# PIC32CX2051BZ66048 register map
Vendor: Microchip Technology; Series: PIC32CXBZ66; File version: 0
CPU: CM4 r0p1, little endian, MPU, FPU, 3 interrupt priority bits, 58 interrupts
Registers are 32-bit, read-write, reset 0x0 unless marked. A register's access mark holds for its fields unless they carry their own. Offsets are from the block's base; [hi:lo] are bit positions; {n}, {i} and the like mark numbered series.

## GPIOE — GPIO
Base 0x44002D00; register names take the prefix GPIO_
Same registers: GPIOA 0x44002900, GPIOB 0x44002A00, GPIOC 0x44002B00, GPIOD 0x44002C00
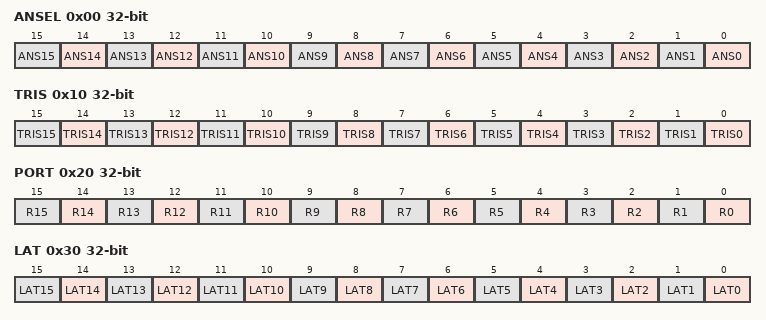
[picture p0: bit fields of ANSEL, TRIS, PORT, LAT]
0x00 ANSEL
  [n] ANS{n} (n=0..15)
0x04 ANSELCLR
0x08 ANSELSET
0x0C ANSELINV
0x10 TRIS
  [n] TRIS{n} (n=0..15)
0x14 TRISCLR
0x18 TRISSET
0x1C TRISINV
0x20 PORT
  [n] R{n} (n=0..15)
0x24 PORTCLR
0x28 PORTSET
0x2C PORTINV
0x30 LAT
  [n] LAT{n} (n=0..15)
0x34 LATCLR
0x38 LATSET
0x3C LATINV
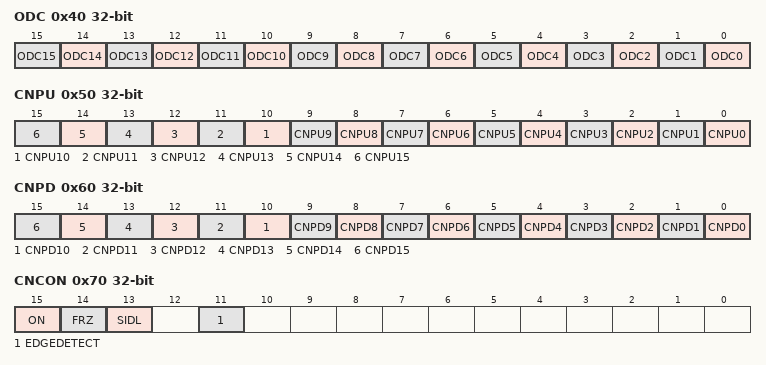
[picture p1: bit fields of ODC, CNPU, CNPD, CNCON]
0x40 ODC
  [n] ODC{n} (n=0..15)
0x44 ODCCLR
0x48 ODCSET
0x4C ODCINV
0x50 CNPU
  [n] CNPU{n} (n=0..15)
0x54 CNPUCLR
0x58 CNPUSET
0x5C CNPUINV
0x60 CNPD
  [n] CNPD{n} (n=0..15)
0x64 CNPDCLR
0x68 CNPDSET
0x6C CNPDINV
0x70 CNCON
  [15] ON, [14] FRZ, [13] SIDL, [11] EDGEDETECT
0x74 CNCONCLR
0x78 CNCONSET
0x7C CNCONINV
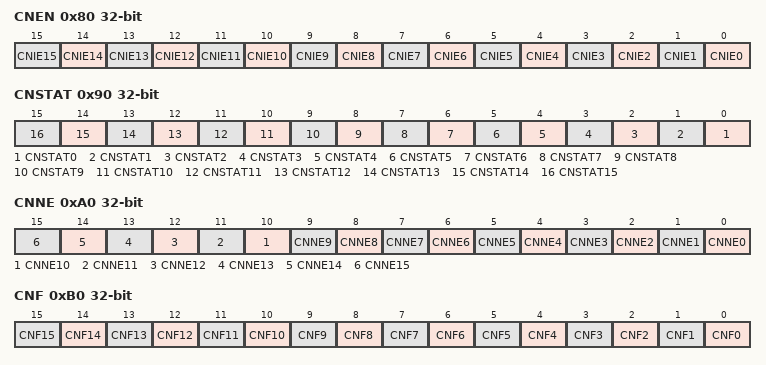
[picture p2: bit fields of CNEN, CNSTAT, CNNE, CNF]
0x80 CNEN
  [n] CNIE{n} (n=0..15)
0x84 CNENCLR
0x88 CNENSET
0x8C CNENINV
0x90 CNSTAT
  [n] CNSTAT{n} (n=0..15)
0x94 CNSTATCLR
0x98 CNSTATSET
0x9C CNSTATINV
0xA0 CNNE
  [n] CNNE{n} (n=0..15)
0xA4 CNNECLR
0xA8 CNNESET
0xAC CNNEINV
0xB0 CNF
  [n] CNF{n} (n=0..15)
0xB4 CNFCLR
0xB8 CNFSET
0xBC CNFINV
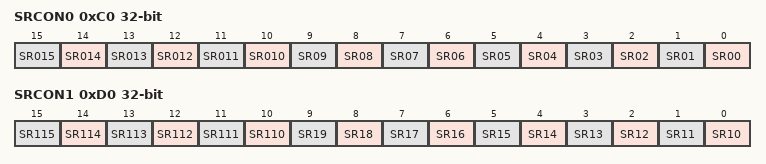
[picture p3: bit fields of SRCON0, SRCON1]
0xC0 SRCON0
  [n] SR{n:03} (n=10..15), [n] SR{n:02} (n=0..9)
0xC4 SRCON0CLR
0xC8 SRCON0SET
0xCC SRCON0INV
0xD0 SRCON1
  [n-100] SR{n} (n=110..115), [n-10] SR{n} (n=10..19)
0xD4 SRCON1CLR
0xD8 SRCON1SET
0xDC SRCON1INV

## HMATRIX2TOP — HSB Matrix
Base 0x42002400
0x80 PRAS0 reset 0x3 — Priority part A for Target 0
0x84 PRBS0 — Priority part B for Target 0
0x88 PRAS1 reset 0x30000300 — Priority part A for Target 1
0x8C PRBS1 — Priority part B for Target 1
0x90 PRAS2 reset 0x3330000 — Priority part A for Target 2
0x94 PRBS2 reset 0x300 — Priority part B for Target 2
0x98 PRAS3 reset 0x3000 — Priority part A for Target 3
0x9C PRBS3 reset 0x33 — Priority part B for Target 3
0xA0 PRAS4 reset 0x30 — Priority part A for Target 4
{0x84+8i} PRBS{i} (i=4..13) — Priority part B for Target {i}
0xA8 PRAS5 reset 0x330303 — Priority part A for Target 5
{0x80+8i} PRAS{i} reset 0x33303 (i=6..9) — Priority part A for Target {i}
0xD0 PRAS10 reset 0x333330 — Priority part A for Target 10
0xD8 PRAS11 reset 0x30 — Priority part A for Target 11
0xE0 PRAS12 reset 0x333303 — Priority part A for Target 12
0xE8 PRAS13 reset 0x33303 — Priority part A for Target 13

## ITM — Instrumentation Trace Macrocell
Base 0xE0000000
{0x0+4i} PORT_BYTE_MODE[{i}] (i=0..31) wo — ITM Stimulus Port Registers
  [7:0] PORT
{0x0+4i} PORT_HWORD_MODE[{i}] (i=0..31) wo (alternate view of PORT_BYTE_MODE[{i}]) — ITM Stimulus Port Registers
  [15:0] PORT
{0x0+4i} PORT_WORD_MODE[{i}] (i=0..31) wo (alternate view of PORT_BYTE_MODE[{i}]) — ITM Stimulus Port Registers
  [31:0] PORT
0xE00 TER — ITM Trace Enable Register
0xE40 TPR — ITM Trace Privilege Register
  [3:0] PRIVMASK
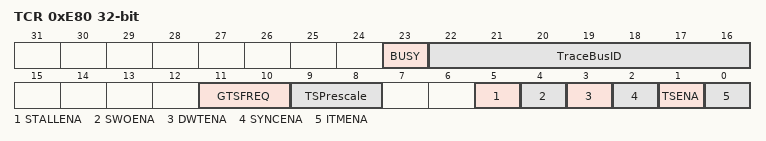
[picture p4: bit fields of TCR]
0xE80 TCR — ITM Trace Control Register
  [23] BUSY, [22:16] TraceBusID, [11:10] GTSFREQ, [9:8] TSPrescale, [5] STALLENA, [4] SWOENA, [3] DWTENA, [2] SYNCENA, [1] TSENA, [0] ITMENA
0xEF8 IWR wo — ITM Integration Write Register
  [0] ATVALIDM
0xEFC IRR ro — ITM Integration Read Register
  [0] ATREADYM
0xFD0 PID4 ro reset 0x4 — ITM Peripheral Identification Register #4
{0xFC0+4i} PID{i} ro (i=5..7) — ITM Peripheral Identification Register #{i}
0xFE0 PID0 ro reset 0x1 — ITM Peripheral Identification Register #0
0xFE4 PID1 ro reset 0xB0 — ITM Peripheral Identification Register #1
0xFE8 PID2 ro reset 0x3B — ITM Peripheral Identification Register #2
0xFEC PID3 ro — ITM Peripheral Identification Register #3
0xFF0 CID0 ro reset 0xD — ITM Component Identification Register #0
0xFF4 CID1 ro reset 0xE0 — ITM Component Identification Register #1
0xFF8 CID2 ro reset 0x5 — ITM Component Identification Register #2
0xFFC CID3 ro reset 0xB1 — ITM Component Identification Register #3
